# Qorvo_SVD register map
Vendor: Qorvo Inc; Series: ARMCM4; File version: 1.0
Registers are 8-bit, read-write, reset 0x0 unless marked. A register's access mark holds for its fields unless they carry their own. Offsets are from the block's base; [hi:lo] are bit positions; {n}, {i} and the like mark numbered series.

## PWMS
Base 0x40001400
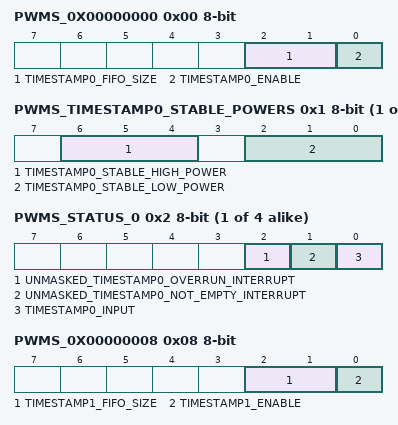
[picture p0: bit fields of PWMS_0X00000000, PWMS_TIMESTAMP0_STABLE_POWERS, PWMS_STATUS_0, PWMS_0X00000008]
0x00 PWMS_0X00000000
  [2:1] TIMESTAMP0_FIFO_SIZE — When set to 1, the timestamp0 fifos works in 16-bit word mode. In this mode, reading the timestamp0_main property, pops an entry from the FIFO. When set to 0, the timestamp0 fifo works in byte mode. In this mode, writing the timestamp0 property pops an entry from the fifo.
  [0] TIMESTAMP0_ENABLE — Enables the timestamp0 functinality.
{0x1+8i} PWMS_TIMESTAMP{i}_STABLE_POWERS (i=0..3)
  [6:4] TIMESTAMP{i}_STABLE_HIGH_POWER — The amount of timestamp{i} input signal processing clock cycles that the input signal has to be high before the processed signal becomes high is (2**timestamp{i}_stable_high_power)-1
  [2:0] TIMESTAMP{i}_STABLE_LOW_POWER — The amount of timestamp{i} input signal processing clock cycles that the input signal has to be low before the processed signal becomes low is (2**timestamp{i}_stable_low_power)-1
{0x2+8i} PWMS_STATUS_{i} ro (i=0..3)
  [2] UNMASKED_TIMESTAMP{i}_OVERRUN_INTERRUPT — The unmasked interrupt status of the timestamp{i} overrun interrupt
  [1] UNMASKED_TIMESTAMP{i}_NOT_EMPTY_INTERRUPT — The unmasked interrupt status of the timestamp{i} not empty interrupt
  [0] TIMESTAMP{i}_INPUT — The current value of the timestamp{i} input
0x08 PWMS_0X00000008
  [2:1] TIMESTAMP1_FIFO_SIZE — When set to 1, the timestamp1 fifos works in 16-bit word mode. In this mode, reading the timestamp1_main property, pops an entry from the FIFO. When set to 0, the timestamp1 fifo works in byte mode. In this mode, writing the timestamp1 property pops an entry from the fifo.
  [0] TIMESTAMP1_ENABLE — Enables the timestamp1 functinality.
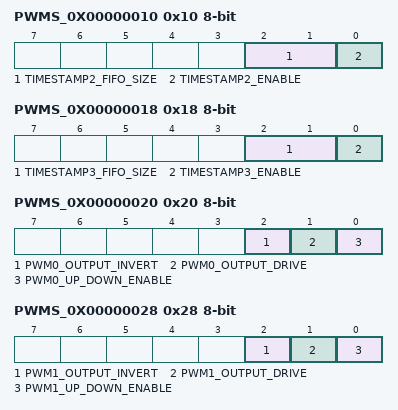
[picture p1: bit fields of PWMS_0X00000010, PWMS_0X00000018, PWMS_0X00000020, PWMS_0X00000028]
0x10 PWMS_0X00000010
  [2:1] TIMESTAMP2_FIFO_SIZE — When set to 1, the timestamp2 fifos works in 16-bit word mode. In this mode, reading the timestamp2_main property, pops an entry from the FIFO. When set to 0, the timestamp2 fifo works in byte mode. In this mode, writing the timestamp2 property pops an entry from the fifo.
  [0] TIMESTAMP2_ENABLE — Enables the timestamp2 functinality.
0x18 PWMS_0X00000018
  [2:1] TIMESTAMP3_FIFO_SIZE — When set to 1, the timestamp3 fifos works in 16-bit word mode. In this mode, reading the timestamp3_main property, pops an entry from the FIFO. When set to 0, the timestamp3 fifo works in byte mode. In this mode, writing the timestamp3 property pops an entry from the fifo.
  [0] TIMESTAMP3_ENABLE — Enables the timestamp3 functinality.
0x20 PWMS_0X00000020
  [2] PWM0_OUTPUT_INVERT — Inverts the output of pwm0
  [1] PWM0_OUTPUT_DRIVE — Sets the drive type for the output of pwm0
  [0] PWM0_UP_DOWN_ENABLE — Enables the up/down mode of pwm0
{0x21+8i} PWMS_THRESHOLD_UPDATE_ON_CARRIER_COUNTER_WRAPS_{i} (i=0..7)
  [0] PWM{i}_THRESHOLD_UPDATE_ON_CARRIER_COUNTER_WRAP — When set to 1, a wrap of the carrier counter will trigger an update of the threshold of pwm{i}.
0x22 PWMS_0X00000022 16-bit ro
  [15:0] PWM0_THRESHOLD — The current value of the threshold of pwm0
{0x24+8i} PWMS_UNMASKED_PWM{i}_INTERRUPTS ro (i=0..7)
  [0] UNMASKED_PWM{i}_THRESHOLD_MATCH_INTERRUPT — The unmasked interrupt status of the threshold match interrupt of pwm{i}
0x28 PWMS_0X00000028
  [2] PWM1_OUTPUT_INVERT — Inverts the output of pwm1
  [1] PWM1_OUTPUT_DRIVE — Sets the drive type for the output of pwm1
  [0] PWM1_UP_DOWN_ENABLE — Enables the up/down mode of pwm1
0x2A PWMS_0X0000002A 16-bit ro
  [15:0] PWM1_THRESHOLD — The current value of the threshold of pwm1
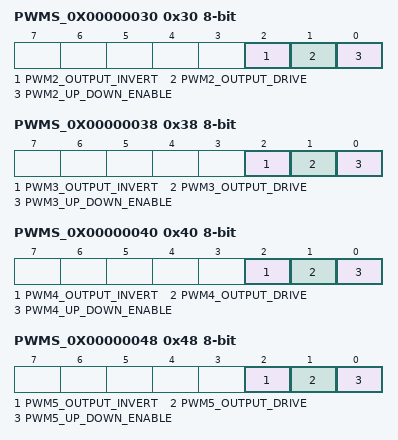
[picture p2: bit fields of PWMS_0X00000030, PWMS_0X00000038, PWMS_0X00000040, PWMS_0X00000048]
0x30 PWMS_0X00000030
  [2] PWM2_OUTPUT_INVERT — Inverts the output of pwm2
  [1] PWM2_OUTPUT_DRIVE — Sets the drive type for the output of pwm2
  [0] PWM2_UP_DOWN_ENABLE — Enables the up/down mode of pwm2
0x32 PWMS_0X00000032 16-bit ro
  [15:0] PWM2_THRESHOLD — The current value of the threshold of pwm2
0x38 PWMS_0X00000038
  [2] PWM3_OUTPUT_INVERT — Inverts the output of pwm3
  [1] PWM3_OUTPUT_DRIVE — Sets the drive type for the output of pwm3
  [0] PWM3_UP_DOWN_ENABLE — Enables the up/down mode of pwm3
0x3A PWMS_0X0000003A 16-bit ro
  [15:0] PWM3_THRESHOLD — The current value of the threshold of pwm3
0x40 PWMS_0X00000040
  [2] PWM4_OUTPUT_INVERT — Inverts the output of pwm4
  [1] PWM4_OUTPUT_DRIVE — Sets the drive type for the output of pwm4
  [0] PWM4_UP_DOWN_ENABLE — Enables the up/down mode of pwm4
0x42 PWMS_0X00000042 16-bit ro
  [15:0] PWM4_THRESHOLD — The current value of the threshold of pwm4
0x48 PWMS_0X00000048
  [2] PWM5_OUTPUT_INVERT — Inverts the output of pwm5
  [1] PWM5_OUTPUT_DRIVE — Sets the drive type for the output of pwm5
  [0] PWM5_UP_DOWN_ENABLE — Enables the up/down mode of pwm5
0x4A PWMS_0X0000004A 16-bit ro
  [15:0] PWM5_THRESHOLD — The current value of the threshold of pwm5
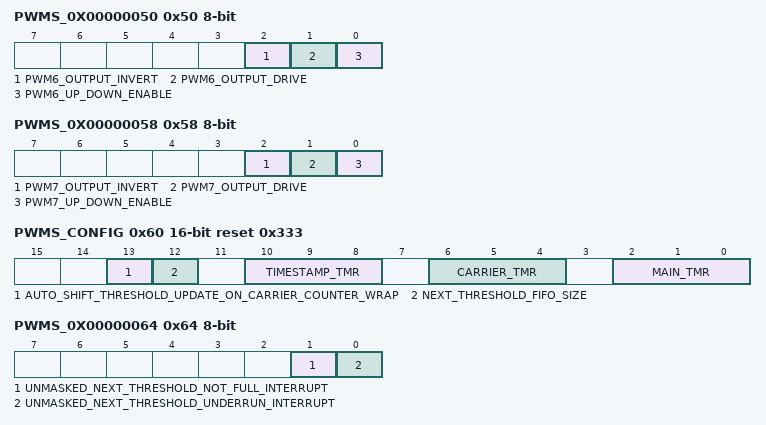
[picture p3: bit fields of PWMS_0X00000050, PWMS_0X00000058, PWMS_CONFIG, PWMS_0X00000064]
0x50 PWMS_0X00000050
  [2] PWM6_OUTPUT_INVERT — Inverts the output of pwm6
  [1] PWM6_OUTPUT_DRIVE — Sets the drive type for the output of pwm6
  [0] PWM6_UP_DOWN_ENABLE — Enables the up/down mode of pwm6
0x52 PWMS_0X00000052 16-bit ro
  [15:0] PWM6_THRESHOLD — The current value of the threshold of pwm6
0x58 PWMS_0X00000058
  [2] PWM7_OUTPUT_INVERT — Inverts the output of pwm7
  [1] PWM7_OUTPUT_DRIVE — Sets the drive type for the output of pwm7
  [0] PWM7_UP_DOWN_ENABLE — Enables the up/down mode of pwm7
0x5A PWMS_0X0000005A 16-bit ro
  [15:0] PWM7_THRESHOLD — The current value of the threshold of pwm7
0x60 PWMS_CONFIG 16-bit reset 0x333
  [13] AUTO_SHIFT_THRESHOLD_UPDATE_ON_CARRIER_COUNTER_WRAP — Automatically perform a logical shift on the 'threshold update on carrier counter wrap' value, on each carrier counter wrap.
  [12] NEXT_THRESHOLD_FIFO_SIZE — When set to 1, the next threshold fifo works in 16-bit word mode. In this mode, writing the next_threshold property, pushes an entry in the FIFO. When set to 0, the next threshold fifo works in byte mode. In this mode, writing the next_threshold_0 property pushes an entry in the fifo.
  [10:8] TIMESTAMP_TMR — timer wrap to use as trigger to check the timestamp input value for the timestamp stable logic
  [6:4] CARRIER_TMR — timer counter value to use as carrier counter value, only lower 7 bits are used
  [2:0] MAIN_TMR — timer counter value to use as main counter value (16 bit)
0x64 PWMS_0X00000064 ro
  [1] UNMASKED_NEXT_THRESHOLD_NOT_FULL_INTERRUPT — The unmasked interrupt status of the next threshold not full interrupt
  [0] UNMASKED_NEXT_THRESHOLD_UNDERRUN_INTERRUPT — The unmasked interrupt status of the next threshold underrun interrupt
